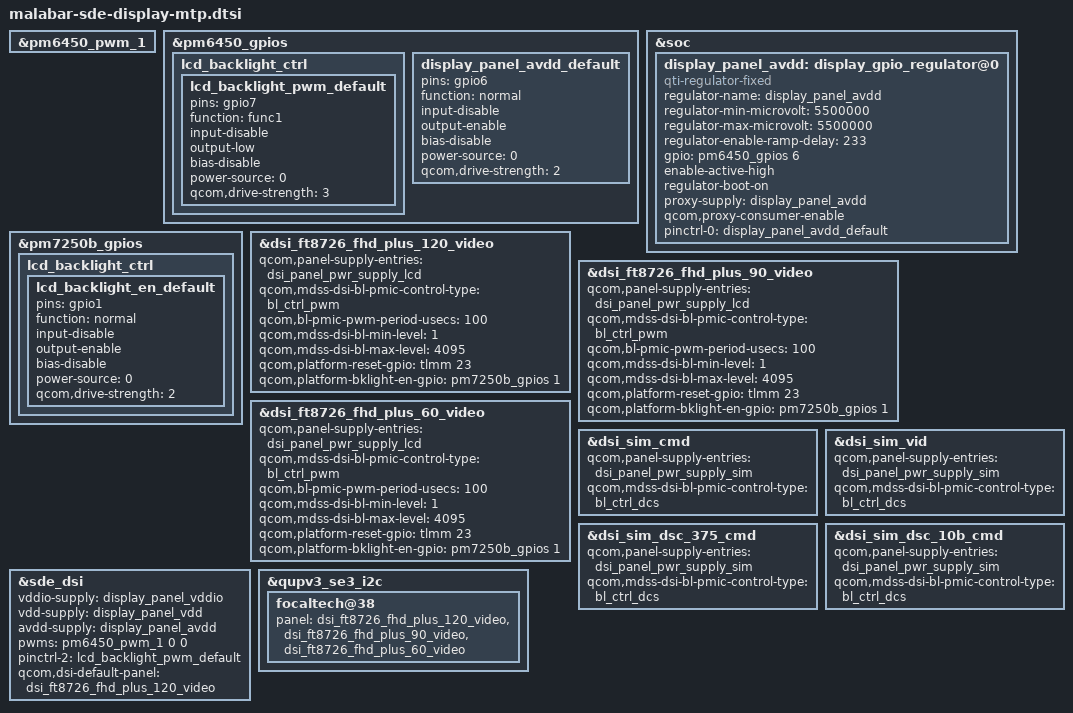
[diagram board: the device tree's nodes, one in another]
// SPDX-License-Identifier: BSD-3-Clause
/*
 * Copyright (c) Qualcomm Technologies, Inc. and/or its subsidiaries.
 */

#include "malabar-sde-display.dtsi"

&pm6450_pwm_1 {
	status = "okay";
};

&pm6450_gpios {
	lcd_backlight_ctrl {
		lcd_backlight_pwm_default: lcd_backlight_pwm_default {
			pins = "gpio7";
			function = "func1";
			input-disable;
			output-low;
			bias-disable;
			power-source = <0>;
			qcom,drive-strength = <3>;
		};
	};

	display_panel_avdd_default: display_panel_avdd_default {
		pins = "gpio6";
		function = "normal";
		input-disable;
		output-enable;
		bias-disable;
		power-source = <0>;
		qcom,drive-strength = <2>;
	};
};

&soc {
	display_panel_avdd: display_gpio_regulator@0 {
		compatible = "qti-regulator-fixed";
		regulator-name = "display_panel_avdd";
		regulator-min-microvolt = <5500000>;
		regulator-max-microvolt = <5500000>;
		regulator-enable-ramp-delay = <233>;
		gpio = <&pm6450_gpios 6 0>;
		enable-active-high;
		regulator-boot-on;
		proxy-supply = <&display_panel_avdd>;
		qcom,proxy-consumer-enable;
		pinctrl-names = "default";
		pinctrl-0 = <&display_panel_avdd_default>;
	};
};

&pm7250b_gpios {
	lcd_backlight_ctrl  {
		lcd_backlight_en_default: lcd_backlight_en_default  {
			pins = "gpio1";
			function = "normal";
			input-disable;
			output-enable;
			bias-disable;
			power-source = <0>;
			qcom,drive-strength = <2>;
		};
	};
};

&dsi_ft8726_fhd_plus_120_video {
	qcom,panel-supply-entries = <&dsi_panel_pwr_supply_lcd>;
	qcom,mdss-dsi-bl-pmic-control-type = "bl_ctrl_pwm";
	qcom,bl-pmic-pwm-period-usecs = <100>;
	qcom,mdss-dsi-bl-min-level = <1>;
	qcom,mdss-dsi-bl-max-level = <4095>;
	qcom,platform-reset-gpio = <&tlmm 23 0>;
	qcom,platform-bklight-en-gpio = <&pm7250b_gpios 1 0>;
};

&dsi_ft8726_fhd_plus_90_video {
	qcom,panel-supply-entries = <&dsi_panel_pwr_supply_lcd>;
	qcom,mdss-dsi-bl-pmic-control-type = "bl_ctrl_pwm";
	qcom,bl-pmic-pwm-period-usecs = <100>;
	qcom,mdss-dsi-bl-min-level = <1>;
	qcom,mdss-dsi-bl-max-level = <4095>;
	qcom,platform-reset-gpio = <&tlmm 23 0>;
	qcom,platform-bklight-en-gpio = <&pm7250b_gpios 1 0>;
};

&dsi_ft8726_fhd_plus_60_video {
	qcom,panel-supply-entries = <&dsi_panel_pwr_supply_lcd>;
	qcom,mdss-dsi-bl-pmic-control-type = "bl_ctrl_pwm";
	qcom,bl-pmic-pwm-period-usecs = <100>;
	qcom,mdss-dsi-bl-min-level = <1>;
	qcom,mdss-dsi-bl-max-level = <4095>;
	qcom,platform-reset-gpio = <&tlmm 23 0>;
	qcom,platform-bklight-en-gpio = <&pm7250b_gpios 1 0>;
};

&dsi_sim_cmd {
	qcom,panel-supply-entries = <&dsi_panel_pwr_supply_sim>;
	qcom,mdss-dsi-bl-pmic-control-type = "bl_ctrl_dcs";
};

&dsi_sim_vid {
	qcom,panel-supply-entries = <&dsi_panel_pwr_supply_sim>;
	qcom,mdss-dsi-bl-pmic-control-type = "bl_ctrl_dcs";
};

&dsi_sim_dsc_375_cmd {
	qcom,panel-supply-entries = <&dsi_panel_pwr_supply_sim>;
	qcom,mdss-dsi-bl-pmic-control-type = "bl_ctrl_dcs";
};

&dsi_sim_dsc_10b_cmd {
	qcom,panel-supply-entries = <&dsi_panel_pwr_supply_sim>;
	qcom,mdss-dsi-bl-pmic-control-type = "bl_ctrl_dcs";
};

&sde_dsi {
	vddio-supply = <&display_panel_vddio>;
	vdd-supply = <&display_panel_vdd>;
	avdd-supply = <&display_panel_avdd>;

	pwms = <&pm6450_pwm_1 0 0>;

	pinctrl-names = "panel_active", "panel_suspend", "pwm_pin";
	pinctrl-2 = <&lcd_backlight_pwm_default>;

	qcom,dsi-default-panel = <&dsi_ft8726_fhd_plus_120_video>;
};

&qupv3_se3_i2c {
	focaltech@38 {
		panel = <&dsi_ft8726_fhd_plus_120_video
			&dsi_ft8726_fhd_plus_90_video
			&dsi_ft8726_fhd_plus_60_video>;
	};
};

